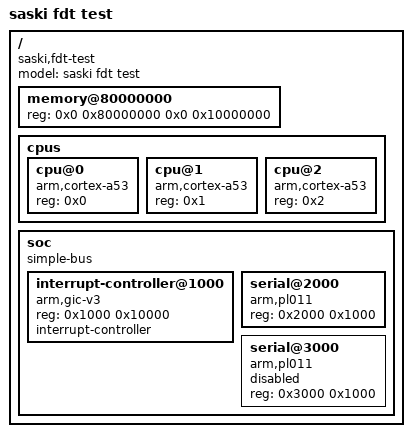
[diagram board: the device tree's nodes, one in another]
/* SPDX-License-Identifier: 0BSD */
/*
 * The device tree the FDT reader is tested against. It is deliberately NOT
 * tests/qemu-virt.dts: this parser fixture exercises cases the QEMU boot
 * fixture does not readily show in a form that can be asserted on.
 *
 * Three things here exist because they are the ones DTB readers get wrong:
 *
 *   - a NON-IDENTITY `ranges`. /soc maps its own address window 0x0..0x10000
 *     onto 0x80000000..0x80010000, so serial@2000 must translate to
 *     0x80002000. QEMU's virt machine maps everything identically, which
 *     means a reader with no ranges support at all still looks correct there.
 *     That is exactly why this tree is not the virt tree.
 *
 *   - TWO-ENTRY compatible lists on the GIC and the UART. A "compatible"
 *     value is a NUL-separated preference list, and a driver registered for
 *     the second entry is still the right driver. Matching only entry zero is
 *     the classic bug, so the suite asserts both entries.
 *
 *   - a DISABLED device. Firmware ships devices disabled and expects them
 *     ignored; counting one as live produces a plausible device that does not
 *     exist, which is worse than not finding it.
 *
 * /memreserve/ is present so the reservation-block reader has something to
 * find, and there are three cpus so child iteration has to count rather than
 * just find the first.
 */

/dts-v1/;
/memreserve/ 0x80000000 0x1000;

/ {
    #address-cells = <2>;
    #size-cells = <2>;
    compatible = "saski,fdt-test";
    model = "saski fdt test";

    memory@80000000 {
        device_type = "memory";
        reg = <0x0 0x80000000 0x0 0x10000000>;
    };

    cpus {
        #address-cells = <1>;
        #size-cells = <0>;
        cpu@0 { device_type = "cpu"; reg = <0x0>; compatible = "arm,cortex-a53"; };
        cpu@1 { device_type = "cpu"; reg = <0x1>; compatible = "arm,cortex-a53"; };
        cpu@2 { device_type = "cpu"; reg = <0x2>; compatible = "arm,cortex-a53"; };
    };

    soc {
        #address-cells = <1>;
        #size-cells = <1>;
        compatible = "simple-bus";
        /* (child addr cells=1)(parent addr cells=2)(size cells=1) */
        ranges = <0x0 0x0 0x80000000 0x10000>;

        interrupt-controller@1000 {
            compatible = "arm,gic-v3", "arm,gic";
            reg = <0x1000 0x10000>;
            interrupt-controller;
            #interrupt-cells = <3>;
        };

        serial@2000 {
            compatible = "arm,pl011", "arm,primecell";
            reg = <0x2000 0x1000>;
            status = "okay";
        };

        serial@3000 {
            compatible = "arm,pl011", "arm,primecell";
            reg = <0x3000 0x1000>;
            status = "disabled";
        };
    };
};
